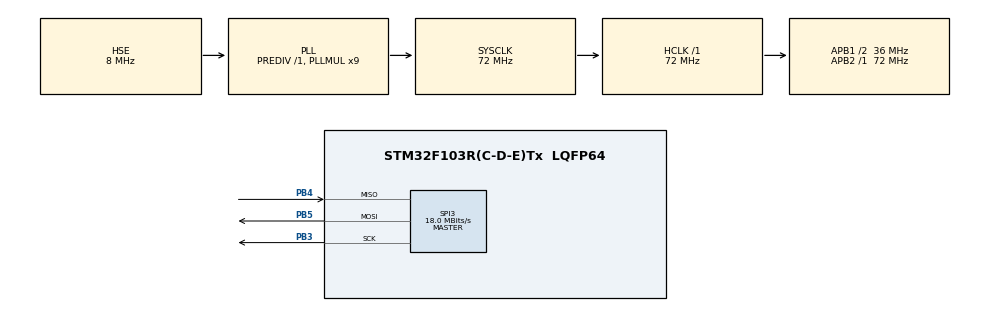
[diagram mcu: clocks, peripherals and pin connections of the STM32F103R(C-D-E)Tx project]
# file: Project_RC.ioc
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Mcu.Family=STM32F1
Mcu.Name=STM32F103R(C-D-E)Tx
Mcu.Package=LQFP64
NVIC.PriorityGroup=NVIC_PRIORITYGROUP_4
NVIC.TIM3_IRQn=true\:1\:0\:true\:true\:true\:1\:true\:true\:true
PA13.Mode=Serial_Wire
PA13.Signal=SYS_JTMS-SWDIO
PA14.Mode=Serial_Wire
PA14.Signal=SYS_JTCK-SWCLK
PB3.Mode=Full_Duplex_Master
PB3.Signal=SPI3_SCK
PB4.Mode=Full_Duplex_Master
PB4.Signal=SPI3_MISO
PB5.Mode=Full_Duplex_Master
PB5.Signal=SPI3_MOSI
PD0-OSC_IN.Mode=HSE-External-Oscillator
PD0-OSC_IN.Signal=RCC_OSC_IN
PD1-OSC_OUT.Mode=HSE-External-Oscillator
PD1-OSC_OUT.Signal=RCC_OSC_OUT
ProjectManager.HeapSize=0x200
ProjectManager.StackSize=0x400
ProjectManager.TargetToolchain=MDK-ARM V5.32
RCC.ADCPresc=RCC_ADCPCLK2_DIV6
RCC.AHBFreq_Value=72000000
RCC.APB1CLKDivider=RCC_HCLK_DIV2
RCC.APB1Freq_Value=36000000
RCC.APB1TimFreq_Value=72000000
RCC.APB2Freq_Value=72000000
RCC.APB2TimFreq_Value=72000000
RCC.HCLKFreq_Value=72000000
RCC.PLLMUL=RCC_PLL_MUL9
RCC.PLLSourceVirtual=RCC_PLLSOURCE_HSE
RCC.SYSCLKFreq_VALUE=72000000
RCC.SYSCLKSource=RCC_SYSCLKSOURCE_PLLCLK
RCC.USBFreq_Value=72000000
SPI3.CalculateBaudRate=18.0 MBits/s
SPI3.Direction=SPI_DIRECTION_2LINES
SPI3.Mode=SPI_MODE_MASTER
SPI3.VirtualType=VM_MASTER
TIM3.Period=9999
TIM3.Prescaler=71
VP_TIM3_VS_ClockSourceINT.Mode=Internal
board=custom

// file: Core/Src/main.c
/* USER CODE BEGIN Header */
/**
  ******************************************************************************
  * @file           : main.c
  * @brief          : Main program body
  ******************************************************************************
  * @attention
  *
  * Copyright (c) 2025 STMicroelectronics.
  * All rights reserved.
  *
  * This software is licensed under terms that can be found in the LICENSE file
  * in the root directory of this software component.
  * If no LICENSE file comes with this software, it is provided AS-IS.
  *
  ******************************************************************************
  */
/* USER CODE END Header */
#include "main.h"
#include "spi.h"
#include "tim.h"
#include "gpio.h"

/* USER CODE BEGIN Includes */
#include "function.h"
/* USER CODE END Includes */

void SystemClock_Config(void);
static void MX_NVIC_Init(void);

/* USER CODE BEGIN 0 */
#define CPU_FREQUENCY_MHZ    72

void delay_us(__IO uint32_t delay)
{
  int last, curr, val;
  int temp;

  while (delay != 0)
  {
    temp = delay > 900 ? 900 : delay;
    last = SysTick->VAL;
    curr = last - CPU_FREQUENCY_MHZ * temp;
    if (curr >= 0)
    {
      do
      {
        val = SysTick->VAL;
      }
      while ((val < last) && (val >= curr));
    }
    else
    {
      curr += CPU_FREQUENCY_MHZ * 1000;
      do
      {
        val = SysTick->VAL;
      }
      while ((val <= last) || (val > curr));
    }
    delay -= temp;
  }
}

/* USER CODE END 0 */

int main(void)
{

  /* MCU Configuration--------------------------------------------------------*/

  /* Reset of all peripherals, Initializes the Flash interface and the Systick. */
  HAL_Init();

  /* Configure the system clock */
  SystemClock_Config();

  /* Initialize all configured peripherals */
  MX_GPIO_Init();
  MX_TIM3_Init();
  MX_SPI3_Init();

  /* Initialize interrupts */
  MX_NVIC_Init();
  /* USER CODE BEGIN 2 */
  RX8025T_Init();
  AT24C64_Init();
  BCD_Init();
  AD_DA_Init();
  HMI_USART_Init();
  FIBER_485_USART_Init();
  RS485_USART_Init();
  CMD_Input_Init();
  /* USER CODE END 2 */

  /* Infinite loop */
  /* USER CODE BEGIN WHILE */
  while (1)
  {
		MainFunction();
    /* USER CODE END WHILE */

  }
}

void SystemClock_Config(void)
{
  RCC_OscInitTypeDef RCC_OscInitStruct = {0};
  RCC_ClkInitTypeDef RCC_ClkInitStruct = {0};

  /** Initializes the RCC Oscillators according to the specified parameters
  * in the RCC_OscInitTypeDef structure.
  */
  RCC_OscInitStruct.OscillatorType = RCC_OSCILLATORTYPE_HSE;
  RCC_OscInitStruct.HSEState = RCC_HSE_ON;
  RCC_OscInitStruct.HSEPredivValue = RCC_HSE_PREDIV_DIV1;
  RCC_OscInitStruct.HSIState = RCC_HSI_ON;
  RCC_OscInitStruct.PLL.PLLState = RCC_PLL_ON;
  RCC_OscInitStruct.PLL.PLLSource = RCC_PLLSOURCE_HSE;
  RCC_OscInitStruct.PLL.PLLMUL = RCC_PLL_MUL9;
  if (HAL_RCC_OscConfig(&RCC_OscInitStruct) != HAL_OK)
  {
    Error_Handler();
  }

  /** Initializes the CPU, AHB and APB buses clocks
  */
  RCC_ClkInitStruct.ClockType = RCC_CLOCKTYPE_HCLK|RCC_CLOCKTYPE_SYSCLK
                              |RCC_CLOCKTYPE_PCLK1|RCC_CLOCKTYPE_PCLK2;
  RCC_ClkInitStruct.SYSCLKSource = RCC_SYSCLKSOURCE_PLLCLK;
  RCC_ClkInitStruct.AHBCLKDivider = RCC_SYSCLK_DIV1;
  RCC_ClkInitStruct.APB1CLKDivider = RCC_HCLK_DIV2;
  RCC_ClkInitStruct.APB2CLKDivider = RCC_HCLK_DIV1;

  if (HAL_RCC_ClockConfig(&RCC_ClkInitStruct, FLASH_LATENCY_2) != HAL_OK)
  {
    Error_Handler();
  }
}

/**
  * @brief NVIC Configuration.
  * @retval None
  */
static void MX_NVIC_Init(void)
{
  /* TIM3_IRQn interrupt configuration */
  HAL_NVIC_SetPriority(TIM3_IRQn, 1, 0);
  HAL_NVIC_EnableIRQ(TIM3_IRQn);
}

void Error_Handler(void)
{
  __disable_irq();
  while (1)
  {
  }
}
